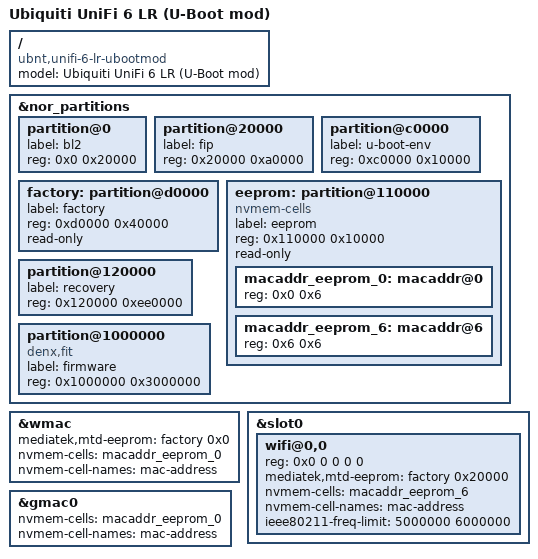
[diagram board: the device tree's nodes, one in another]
// SPDX-License-Identifier: GPL-2.0-or-later OR MIT

#include "mt7622-ubnt-unifi-6-lr.dtsi"

/ {
	model = "Ubiquiti UniFi 6 LR (U-Boot mod)";
	compatible = "ubnt,unifi-6-lr-ubootmod", "mediatek,mt7622";
};

&nor_partitions {
	partition@0 {
		label = "bl2";
		reg = <0x0 0x20000>;
	};

	partition@20000 {
		label = "fip";
		reg = <0x20000 0xa0000>;
	};

	partition@c0000 {
		label = "u-boot-env";
		reg = <0xc0000 0x10000>;
	};

	factory: partition@d0000 {
		label = "factory";
		reg = <0xd0000 0x40000>;
		read-only;
	};

	eeprom: partition@110000 {
		label = "eeprom";
		reg = <0x110000 0x10000>;
		read-only;
	};

	partition@120000 {
		label = "recovery";
		reg = <0x120000 0xee0000>;
	};

	partition@1000000 {
		compatible = "denx,fit";
		label = "firmware";
		reg = <0x1000000 0x3000000>;
	};
};

&wmac {
	mediatek,mtd-eeprom = <&factory 0x0>;
	nvmem-cells = <&macaddr_eeprom_0>;
	nvmem-cell-names = "mac-address";
	status = "okay";
};

&slot0 {
	wifi@0,0 {
		reg = <0x0 0 0 0 0>;
		mediatek,mtd-eeprom = <&factory 0x20000>;
		nvmem-cells = <&macaddr_eeprom_6>;
		nvmem-cell-names = "mac-address";
		ieee80211-freq-limit = <5000000 6000000>;
	};
};

&gmac0 {
	nvmem-cells = <&macaddr_eeprom_0>;
	nvmem-cell-names = "mac-address";
};

&eeprom {
	compatible = "nvmem-cells";
	#address-cells = <1>;
	#size-cells = <1>;

	macaddr_eeprom_0: macaddr@0 {
		reg = <0x0 0x6>;
	};

	macaddr_eeprom_6: macaddr@6 {
		reg = <0x6 0x6>;
	};
};
